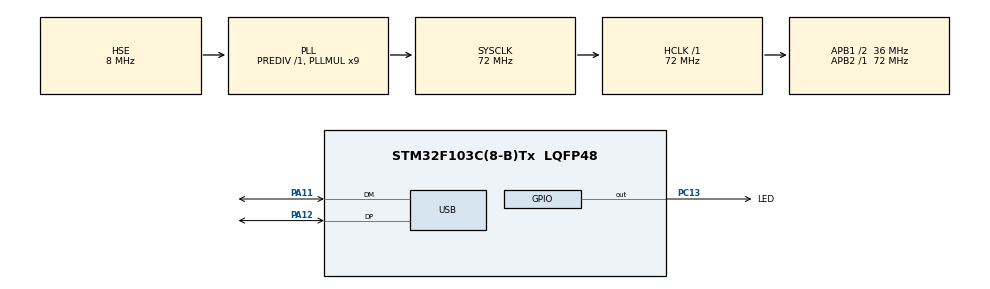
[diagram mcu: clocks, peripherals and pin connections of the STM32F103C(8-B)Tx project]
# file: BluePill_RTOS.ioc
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FREERTOS.INCLUDE_vTaskDelayUntil=1
FREERTOS.Tasks01=defaultTask,0,128,StartDefaultTask,Default,NULL,Dynamic,NULL,NULL
FREERTOS.configUSE_COUNTING_SEMAPHORES=1
Mcu.Family=STM32F1
Mcu.Name=STM32F103C(8-B)Tx
Mcu.Package=LQFP48
NVIC.PriorityGroup=NVIC_PRIORITYGROUP_4
NVIC.TIM1_UP_IRQn=true\:0\:0\:false\:false\:true\:false\:false\:true
NVIC.TimeBase=TIM1_UP_IRQn
NVIC.TimeBaseIP=TIM1
NVIC.USB_LP_CAN1_RX0_IRQn=true\:5\:0\:true\:false\:true\:true\:true\:true
PA11.Mode=Device
PA11.Signal=USB_DM
PA12.Mode=Device
PA12.Signal=USB_DP
PA13.Mode=Serial_Wire
PA13.Signal=SYS_JTMS-SWDIO
PA14.Mode=Serial_Wire
PA14.Signal=SYS_JTCK-SWCLK
PC13-TAMPER-RTC.GPIO_Label=LED
PC13-TAMPER-RTC.Signal=GPIO_Output
PD0-OSC_IN.Mode=HSE-External-Oscillator
PD0-OSC_IN.Signal=RCC_OSC_IN
PD1-OSC_OUT.Mode=HSE-External-Oscillator
PD1-OSC_OUT.Signal=RCC_OSC_OUT
ProjectManager.HeapSize=0x400
ProjectManager.StackSize=0x800
ProjectManager.TargetToolchain=MDK-ARM V5.27
RCC.AHBFreq_Value=72000000
RCC.APB1CLKDivider=RCC_HCLK_DIV2
RCC.APB1Freq_Value=36000000
RCC.APB1TimFreq_Value=72000000
RCC.APB2Freq_Value=72000000
RCC.APB2TimFreq_Value=72000000
RCC.HCLKFreq_Value=72000000
RCC.PLLMUL=RCC_PLL_MUL9
RCC.PLLSourceVirtual=RCC_PLLSOURCE_HSE
RCC.SYSCLKFreq_VALUE=72000000
RCC.SYSCLKSource=RCC_SYSCLKSOURCE_PLLCLK
RCC.USBFreq_Value=48000000
RCC.USBPrescaler=RCC_USBCLKSOURCE_PLL_DIV1_5
USB_DEVICE.CLASS_NAME_FS=CDC
USB_DEVICE.VirtualMode=Cdc
USB_DEVICE.VirtualModeFS=Cdc_FS
VP_FREERTOS_VS_CMSIS_V1.Mode=CMSIS_V1
VP_SYS_VS_tim1.Mode=TIM1
VP_USB_DEVICE_VS_USB_DEVICE_CDC_FS.Mode=CDC_FS
board=custom

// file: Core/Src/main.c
/* USER CODE BEGIN Header */
/**
  ******************************************************************************
  * @file           : main.c
  * @brief          : Main program body
  ******************************************************************************
  * @attention
  *
  * <h2><center>&copy; Copyright (c) 2021 STMicroelectronics.
  * All rights reserved.</center></h2>
  *
  * This software component is licensed by ST under BSD 3-Clause license,
  * the "License"; You may not use this file except in compliance with the
  * License. You may obtain a copy of the License at:
  *                        opensource.org/licenses/BSD-3-Clause
  *
  ******************************************************************************
  */
/* USER CODE END Header */
#include "main.h"
#include "cmsis_os.h"
#include "usb_device.h"
#include "gpio.h"

/* USER CODE BEGIN Includes */
//#include "FreeRTOS.h"
#include "task.h"
#include "timers.h"
#include "queue.h"
#include "semphr.h"
#include "event_groups.h"

#include <stdio.h>
#include <stdlib.h>
#include <string.h>
#include "StateMach.h"                  /* Model's header file */
#include "rtwtypes.h"
/* USER CODE END Includes */

/* USER CODE BEGIN PM */
#define my_itoa(num, str) sprintf(str, "%d", num)
/* USER CODE END PM */

/* USER CODE BEGIN PV */
  char btn_test = 0;
	uint16_t debouncetime = 100;
/* USER CODE END PV */

void SystemClock_Config(void);
void MX_FREERTOS_Init(void);
/* USER CODE BEGIN PFP */
extern void MX_USB_DEVICE_Init(void);
/* USER CODE END PFP */

/* USER CODE BEGIN 0 */
//Create task defines
TaskHandle_t HPTHandler;
void HPT_TASK (void *pvParameters);

TaskHandle_t MPTHandler;
void MPT_TASK (void *pvParameters);

TaskHandle_t LPTHandler;
void LPT_TASK (void *pvParameters);

TaskHandle_t VLPTHandler;
void VLPT_TASK (void *pvParameters);

//Semaphore related
SemaphoreHandle_t CountingSem;

//Resource Related
int resource[] = {111, 222, 333};
int indx = 0;

//USB Related
uint8_t rx_data = 0;
/* USER CODE END 0 */

int main(void)
{

  /* MCU Configuration--------------------------------------------------------*/

  /* Reset of all peripherals, Initializes the Flash interface and the Systick. */
  HAL_Init();

  /* Configure the system clock */
  SystemClock_Config();

  /* Initialize all configured peripherals */
  MX_GPIO_Init();
  /* USER CODE BEGIN 2 */

  CountingSem = xSemaphoreCreateCounting(3, 0);

  xTaskCreate(HPT_TASK, "HPT", 128, NULL, 3, &HPTHandler);
  xTaskCreate(MPT_TASK, "MPT", 128, NULL, 2, &MPTHandler);
  xTaskCreate(LPT_TASK, "LPT", 128, NULL, 1, &LPTHandler);
  xTaskCreate(VLPT_TASK, "VLPT", 128, NULL, 0, &VLPTHandler);

	MX_USB_DEVICE_Init();
  /* USER CODE END 2 */

  /* Call init function for freertos objects (in freertos.c) */
  MX_FREERTOS_Init();
  /* Start scheduler */
  osKernelStart();

  /* We should never get here as control is now taken by the scheduler */
  /* Infinite loop */
  /* USER CODE BEGIN WHILE */
	//WaitTime_initialize();
  while (1)
  {
    /*
		WaitTime_step();
		HAL_GPIO_TogglePin(LED_GPIO_Port, LED_Pin);
		HAL_Delay(rtY.WaitTime_g);
		*/
    /* USER CODE END WHILE */

  }
}

void SystemClock_Config(void)
{
  RCC_OscInitTypeDef RCC_OscInitStruct = {0};
  RCC_ClkInitTypeDef RCC_ClkInitStruct = {0};
  RCC_PeriphCLKInitTypeDef PeriphClkInit = {0};

  /** Initializes the RCC Oscillators according to the specified parameters
  * in the RCC_OscInitTypeDef structure.
  */
  RCC_OscInitStruct.OscillatorType = RCC_OSCILLATORTYPE_HSE;
  RCC_OscInitStruct.HSEState = RCC_HSE_ON;
  RCC_OscInitStruct.HSEPredivValue = RCC_HSE_PREDIV_DIV1;
  RCC_OscInitStruct.HSIState = RCC_HSI_ON;
  RCC_OscInitStruct.PLL.PLLState = RCC_PLL_ON;
  RCC_OscInitStruct.PLL.PLLSource = RCC_PLLSOURCE_HSE;
  RCC_OscInitStruct.PLL.PLLMUL = RCC_PLL_MUL9;
  if (HAL_RCC_OscConfig(&RCC_OscInitStruct) != HAL_OK)
  {
    Error_Handler();
  }
  /** Initializes the CPU, AHB and APB buses clocks
  */
  RCC_ClkInitStruct.ClockType = RCC_CLOCKTYPE_HCLK|RCC_CLOCKTYPE_SYSCLK
                              |RCC_CLOCKTYPE_PCLK1|RCC_CLOCKTYPE_PCLK2;
  RCC_ClkInitStruct.SYSCLKSource = RCC_SYSCLKSOURCE_PLLCLK;
  RCC_ClkInitStruct.AHBCLKDivider = RCC_SYSCLK_DIV1;
  RCC_ClkInitStruct.APB1CLKDivider = RCC_HCLK_DIV2;
  RCC_ClkInitStruct.APB2CLKDivider = RCC_HCLK_DIV1;

  if (HAL_RCC_ClockConfig(&RCC_ClkInitStruct, FLASH_LATENCY_2) != HAL_OK)
  {
    Error_Handler();
  }
  PeriphClkInit.PeriphClockSelection = RCC_PERIPHCLK_USB;
  PeriphClkInit.UsbClockSelection = RCC_USBCLKSOURCE_PLL_DIV1_5;
  if (HAL_RCCEx_PeriphCLKConfig(&PeriphClkInit) != HAL_OK)
  {
    Error_Handler();
  }
}

/* USER CODE BEGIN 4 */
void HPT_TASK (void *pvParameters)
{
  char sresource[3];
  StateMach_initialize();
  //xSemaphoreGive(CountingSem);
  //xSemaphoreGive(CountingSem);
  //xSemaphoreGive(CountingSem);

  while(1)
  {
    /*
    char str[150];
    strcpy(str, "Entered HPT Task\n About to ACQUIRE the Semaphore\n\n");
    USB_SendMessage(str, strlen(str), 10);

    xSemaphoreTake(CountingSem, portMAX_DELAY);

    my_itoa(resource[indx], sresource);
    strcpy(str, "Leaving HPT Task\n Data ACCESSED is:: ");
    strcat(str, sresource);
    strcat(str, "\n Not Releasing the Semaphore\n\n\n");
    USB_SendMessage(str, strlen(str), 10);

    indx++;
    if(indx > 2)
      indx = 0;
*/
    //Simulink

    /* Inputs */
    rtU.In_Btn = btn_test;
    rtU.In_DebTime = debouncetime;

    StateMach_step();

    HAL_GPIO_WritePin(LED_GPIO_Port, LED_Pin, rtY.Out_Ld);

    vTaskDelay(1);
  }

}
void MPT_TASK (void *pvParameters)
{
  char sresource[3];

  while(1)
  {
    /*
    char str[150];
    strcpy(str, "Entered MPT Task\n About to ACQUIRE the Semaphore\n\n");
    USB_SendMessage(str, strlen(str), 10);

    //xSemaphoreTake(CountingSem, portMAX_DELAY);

    my_itoa(resource[indx], sresource);
    strcpy(str, "Leaving MPT Task\n Data ACCESSED is:: ");
    strcat(str, sresource);
    strcat(str, "\n Not Releasing the Semaphore\n\n\n");
    USB_SendMessage(str, strlen(str), 10);

    indx++;
    if(indx > 2)
      indx = 0;
*/
    vTaskDelay(2000);
  }
}
void LPT_TASK (void *pvParameters)
{
  char sresource[3];

  while(1)
  {
    /*
    char str[150];
    strcpy(str, "Entered LPT Task\n About to ACQUIRE the Semaphore\n\n");
    USB_SendMessage(str, strlen(str), 10);

    //xSemaphoreTake(CountingSem, portMAX_DELAY);

    my_itoa(resource[indx], sresource);
    strcpy(str, "Leaving LPT Task\n Data ACCESSED is:: ");
    strcat(str, sresource);
    strcat(str, "\n Not Releasing the Semaphore\n\n\n");
    USB_SendMessage(str, strlen(str), 10);

    indx++;
    if(indx > 2)
      indx = 0;
*/
    vTaskDelay(1000);
  }
}
void VLPT_TASK (void *pvParameters)
{
    char sresource[3];

  while(1)
  {
    /*
    char str[150];
    strcpy(str, "Entered VLPT Task\n About to ACQUIRE the Semaphore\n\n");
    USB_SendMessage(str, strlen(str), 10);

    //xSemaphoreTake(CountingSem, portMAX_DELAY);

    my_itoa(resource[indx], sresource);
    strcpy(str, "Leaving VLPT Task\n Data ACCESSED is:: ");
    strcat(str, sresource);
    strcat(str, "\n Not Releasing the Semaphore\n\n\n");
    USB_SendMessage(str, strlen(str), 10);

    indx++;
    if(indx > 2)
      indx = 0;
*/
    vTaskDelay(3000);
  }
}

/* USER CODE END 4 */

 /**
  * @brief  Period elapsed callback in non blocking mode
  * @note   This function is called  when TIM1 interrupt took place, inside
  * HAL_TIM_IRQHandler(). It makes a direct call to HAL_IncTick() to increment
  * a global variable "uwTick" used as application time base.
  * @param  htim : TIM handle
  * @retval None
  */
void HAL_TIM_PeriodElapsedCallback(TIM_HandleTypeDef *htim)
{
  if (htim->Instance == TIM1) {
    HAL_IncTick();
  }
}

void Error_Handler(void)
{
  __disable_irq();
  while (1)
  {
  }
}

/************************ (C) COPYRIGHT STMicroelectronics *****END OF FILE****/

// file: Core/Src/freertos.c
/* USER CODE BEGIN Header */
/**
  ******************************************************************************
  * File Name          : freertos.c
  * Description        : Code for freertos applications
  ******************************************************************************
  * @attention
  *
  * <h2><center>&copy; Copyright (c) 2021 STMicroelectronics.
  * All rights reserved.</center></h2>
  *
  * This software component is licensed by ST under Ultimate Liberty license
  * SLA0044, the "License"; You may not use this file except in compliance with
  * the License. You may obtain a copy of the License at:
  *                             www.st.com/SLA0044
  *
  ******************************************************************************
  */
/* USER CODE END Header */

#include "FreeRTOS.h"
#include "task.h"
#include "main.h"
#include "cmsis_os.h"

/* USER CODE BEGIN Includes */
#include <stdio.h>
#include "usb_device.h"
/* USER CODE END Includes */

/* USER CODE BEGIN Variables */

uint8_t received = 0;
/* USER CODE END Variables */
osThreadId defaultTaskHandle;

/* USER CODE BEGIN FunctionPrototypes */
void send_deftask(void)
{
	CDC_Transmit_FS("Hello World!", sizeof("Hello World!"));
}
void send_task2(void)
{
	CDC_Transmit_FS("Hello Another World!\n", sizeof("Hello Another World!\n"));
}
void send_task3(void)
{
	CDC_Transmit_FS("Hello third World!\n", sizeof("Hello third World!\n"));
}

/* USER CODE END FunctionPrototypes */

void StartDefaultTask(void const * argument);

extern void MX_USB_DEVICE_Init(void);
void MX_FREERTOS_Init(void); /* (MISRA C 2004 rule 8.1) */

/* GetIdleTaskMemory prototype (linked to static allocation support) */
void vApplicationGetIdleTaskMemory( StaticTask_t **ppxIdleTaskTCBBuffer, StackType_t **ppxIdleTaskStackBuffer, uint32_t *pulIdleTaskStackSize );

/* USER CODE BEGIN GET_IDLE_TASK_MEMORY */
static StaticTask_t xIdleTaskTCBBuffer;
static StackType_t xIdleStack[configMINIMAL_STACK_SIZE];

void vApplicationGetIdleTaskMemory( StaticTask_t **ppxIdleTaskTCBBuffer, StackType_t **ppxIdleTaskStackBuffer, uint32_t *pulIdleTaskStackSize )
{
  *ppxIdleTaskTCBBuffer = &xIdleTaskTCBBuffer;
  *ppxIdleTaskStackBuffer = &xIdleStack[0];
  *pulIdleTaskStackSize = configMINIMAL_STACK_SIZE;
  /* place for user code */
}
/* USER CODE END GET_IDLE_TASK_MEMORY */

void MX_FREERTOS_Init(void) {

  /* Create the thread(s) */
  /* definition and creation of defaultTask */
  osThreadDef(defaultTask, StartDefaultTask, osPriorityNormal, 0, 128);
  defaultTaskHandle = osThreadCreate(osThread(defaultTask), NULL);

}

void StartDefaultTask(void const * argument)
{
  /* init code for USB_DEVICE */
  MX_USB_DEVICE_Init();
  /* USER CODE BEGIN StartDefaultTask */
  /* Infinite loop */
  for(;;)
  {

		uint8_t temp_buffer[] = "Entered Normal Task!\n\r";
		USB_SendMessage(temp_buffer, sizeof(temp_buffer), 10);

		uint8_t temp_buffer2[] = "Leaving Normal Task!\n\r";
		USB_SendMessage(temp_buffer2, sizeof(temp_buffer2), 10);

    osDelay(500);
  }

  /* USER CODE END StartDefaultTask */
}

/************************ (C) COPYRIGHT STMicroelectronics *****END OF FILE****/
